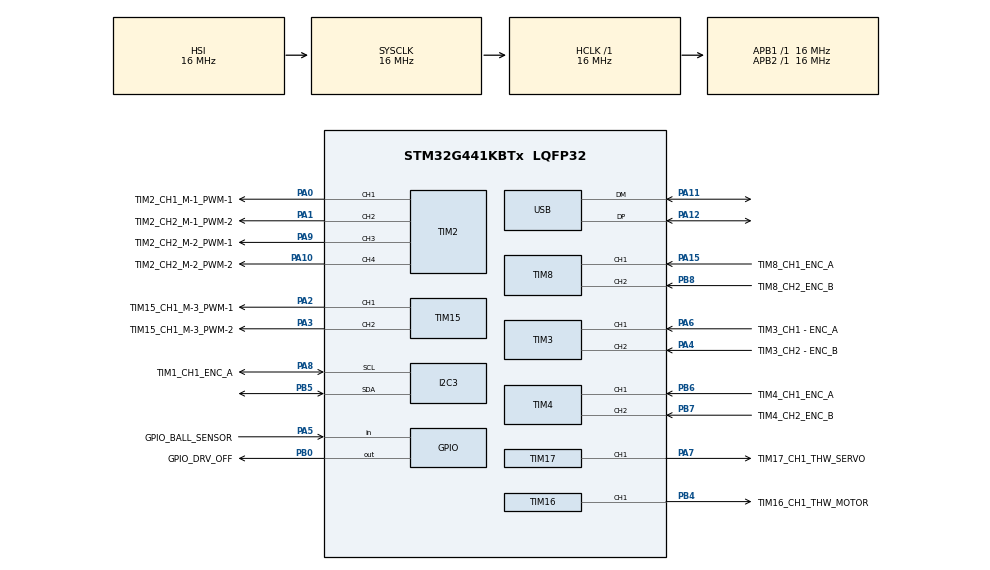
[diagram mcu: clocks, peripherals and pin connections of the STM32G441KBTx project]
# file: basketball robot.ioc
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<<<<<<< HEAD
=======
<<<<<<< HEAD
Mcu.Family=STM32G4
Mcu.Name=STM32G441KBTx
Mcu.Package=LQFP32
NVIC.PriorityGroup=NVIC_PRIORITYGROUP_4
PA0.GPIO_Label=TIM2_CH1_M-1_PWM-1
PA0.Signal=S_TIM2_CH1
PA1.GPIO_Label=TIM2_CH2_M-1_PWM-2
PA1.Signal=S_TIM2_CH2
PA10.GPIO_Label=TIM2_CH2_M-2_PWM-2
PA10.Signal=S_TIM2_CH4
PA11.Mode=Device
PA11.Signal=USB_DM
PA12.Mode=Device
PA12.Signal=USB_DP
PA13.Mode=I2C
PA13.Signal=I2C1_SCL
PA14.Mode=I2C
PA14.Signal=I2C1_SDA
PA15.GPIO_Label=TIM8_CH2_M-3_PWM-1
PA15.Signal=S_TIM8_CH1
PA2.GPIO_Label=TIM2_CH2_M-2_PWM-1
PA2.Signal=S_TIM2_CH3
PA3.GPIO_Label=TIM15_CH2_TH_PWM
PA3.Signal=S_TIM15_CH2
PA4.GPIO_Label=TIM3_CH2 - ENC_B
PA4.Signal=S_TIM3_CH2
PA6.GPIO_Label=TIM3_CH1 - ENC_A
PA6.Signal=S_TIM3_CH1
PA8.GPIO_Label=TIM1_CH1_ENC_A
PA8.Signal=S_TIM1_CH1
PA9.GPIO_Label=TIM1_CH2_ENC_B
PA9.Signal=S_TIM1_CH2
PB6.GPIO_Label=TIM4_CH1_ENC_A
PB6.Signal=S_TIM4_CH1
PB7.GPIO_Label=TIM4_CH2_ENC_B
PB7.Signal=S_TIM4_CH2
PB8-BOOT0.GPIO_Label=TIM8_CH2_M-3_PWM-2 (BOOT0)
PB8-BOOT0.Signal=S_TIM8_CH2
ProjectManager.HeapSize=0x200
ProjectManager.StackSize=0x400
ProjectManager.TargetToolchain=STM32CubeIDE
RCC.AHBFreq_Value=16000000
RCC.APB1Freq_Value=16000000
RCC.APB1TimFreq_Value=16000000
RCC.APB2Freq_Value=16000000
RCC.APB2TimFreq_Value=16000000
RCC.CortexFreq_Value=16000000
RCC.EXTERNAL_CLOCK_VALUE=12288000
RCC.HCLKFreq_Value=16000000
RCC.HSE_VALUE=8000000
RCC.HSI48_VALUE=48000000
RCC.HSI_VALUE=16000000
RCC.LSE_VALUE=32768
RCC.PLLN=12
RCC.PLLQ=RCC_PLLQ_DIV4
RCC.SYSCLKFreq_VALUE=16000000
RCC.USBFreq_Value=48000000
RCC.VCOOutputFreq_Value=192000000
SH.S_TIM15_CH2.0=TIM15_CH2,PWM Generation2 CH2
SH.S_TIM1_CH1.0=TIM1_CH1,Encoder_Interface
SH.S_TIM1_CH2.0=TIM1_CH2,Encoder_Interface
SH.S_TIM2_CH1.0=TIM2_CH1,PWM Generation1 CH1
SH.S_TIM2_CH2.0=TIM2_CH2,PWM Generation2 CH2
SH.S_TIM2_CH3.0=TIM2_CH3,PWM Generation3 CH3
SH.S_TIM2_CH4.0=TIM2_CH4,PWM Generation4 CH4
SH.S_TIM3_CH1.0=TIM3_CH1,Encoder_Interface
SH.S_TIM3_CH2.0=TIM3_CH2,Encoder_Interface
SH.S_TIM4_CH1.0=TIM4_CH1,Encoder_Interface
SH.S_TIM4_CH2.0=TIM4_CH2,Encoder_Interface
SH.S_TIM8_CH1.0=TIM8_CH1,Output Compare1 CH1
SH.S_TIM8_CH2.0=TIM8_CH2,Output Compare2 CH2
TIM15.Channel-PWM\ Generation2\ CH2=TIM_CHANNEL_2
TIM2.Channel-PWM\ Generation1\ CH1=TIM_CHANNEL_1
TIM2.Channel-PWM\ Generation2\ CH2=TIM_CHANNEL_2
TIM2.Channel-PWM\ Generation3\ CH3=TIM_CHANNEL_3
TIM2.Channel-PWM\ Generation4\ CH4=TIM_CHANNEL_4
TIM8.Channel-Output\ Compare1\ CH1=TIM_CHANNEL_1
TIM8.Channel-Output\ Compare2\ CH2=TIM_CHANNEL_2
USB.battery_charging_enable=DISABLE
USB.low_power_enable=DISABLE
USB.lpm_enable=DISABLE
VP_SYS_VS_DBSignals.Mode=DisableDeadBatterySignals
board=custom
=======
>>>>>>> 8d38ac2402675cea33a5d87779682db3a0426ee8
Mcu.Family=STM32G4
Mcu.Name=STM32G441KBTx
Mcu.Package=LQFP32
NVIC.PriorityGroup=NVIC_PRIORITYGROUP_4
PA0.GPIO_Label=TIM2_CH1_M-1_PWM-1
PA0.Signal=S_TIM2_CH1
PA1.GPIO_Label=TIM2_CH2_M-1_PWM-2
PA1.Signal=S_TIM2_CH2
PA10.GPIO_Label=TIM2_CH2_M-2_PWM-2
PA10.Signal=S_TIM2_CH4
PA11.Mode=Device
PA11.Signal=USB_DM
PA12.Mode=Device
PA12.Signal=USB_DP
PA13.Mode=Serial_Wire
PA13.Signal=SYS_JTMS-SWDIO
PA14.Mode=Serial_Wire
PA14.Signal=SYS_JTCK-SWCLK
PA15.GPIO_Label=TIM8_CH1_ENC_A
PA15.Signal=S_TIM8_CH1
PA2.GPIO_Label=TIM15_CH1_M-3_PWM-1
PA2.Signal=S_TIM15_CH1
PA3.GPIO_Label=TIM15_CH1_M-3_PWM-2
PA3.Signal=S_TIM15_CH2
PA4.GPIO_Label=TIM3_CH2 - ENC_B
PA4.Signal=S_TIM3_CH2
PA5.GPIO_Label=GPIO_BALL_SENSOR
PA5.Signal=GPIO_Input
PA6.GPIO_Label=TIM3_CH1 - ENC_A
PA6.Signal=S_TIM3_CH1
PA7.GPIO_Label=TIM17_CH1_THW_SERVO
PA7.Signal=S_TIM17_CH1
PA8.Mode=I2C
PA8.Signal=I2C3_SCL
PA9.GPIO_Label=TIM2_CH2_M-2_PWM-1
PA9.Signal=S_TIM2_CH3
PB0.GPIO_Label=GPIO_DRV_OFF
PB0.Signal=GPIO_Output
PB4.GPIO_Label=TIM16_CH1_THW_MOTOR
PB4.Signal=S_TIM16_CH1
PB5.Mode=I2C
PB5.Signal=I2C3_SDA
PB6.GPIO_Label=TIM4_CH1_ENC_A
PB6.Signal=S_TIM4_CH1
PB7.GPIO_Label=TIM4_CH2_ENC_B
PB7.Signal=S_TIM4_CH2
PB8-BOOT0.GPIO_Label=TIM8_CH2_ENC_B
PB8-BOOT0.Signal=S_TIM8_CH2
ProjectManager.HeapSize=0x200
ProjectManager.StackSize=0x400
ProjectManager.TargetToolchain=STM32CubeIDE
RCC.AHBFreq_Value=16000000
RCC.APB1Freq_Value=16000000
RCC.APB1TimFreq_Value=16000000
RCC.APB2Freq_Value=16000000
RCC.APB2TimFreq_Value=16000000
RCC.CortexFreq_Value=16000000
RCC.EXTERNAL_CLOCK_VALUE=12288000
RCC.HCLKFreq_Value=16000000
RCC.HSE_VALUE=8000000
RCC.HSI48_VALUE=48000000
RCC.HSI_VALUE=16000000
RCC.LSE_VALUE=32768
RCC.PLLN=12
RCC.PLLQ=RCC_PLLQ_DIV4
RCC.SYSCLKFreq_VALUE=16000000
RCC.USBFreq_Value=48000000
RCC.VCOOutputFreq_Value=192000000
SH.S_TIM15_CH1.0=TIM15_CH1,PWM Generation1 CH1
SH.S_TIM15_CH2.0=TIM15_CH2,PWM Generation2 CH2
SH.S_TIM16_CH1.0=TIM16_CH1,PWM Generation1 CH1
SH.S_TIM17_CH1.0=TIM17_CH1,PWM Generation1 CH1
SH.S_TIM2_CH1.0=TIM2_CH1,PWM Generation1 CH1
SH.S_TIM2_CH2.0=TIM2_CH2,PWM Generation2 CH2
SH.S_TIM2_CH3.0=TIM2_CH3,PWM Generation3 CH3
SH.S_TIM2_CH4.0=TIM2_CH4,PWM Generation4 CH4
SH.S_TIM3_CH1.0=TIM3_CH1,Encoder_Interface
SH.S_TIM3_CH2.0=TIM3_CH2,Encoder_Interface
SH.S_TIM4_CH1.0=TIM4_CH1,Encoder_Interface
SH.S_TIM4_CH2.0=TIM4_CH2,Encoder_Interface
SH.S_TIM8_CH1.0=TIM8_CH1,Encoder_Interface
SH.S_TIM8_CH2.0=TIM8_CH2,Encoder_Interface
TIM15.Channel-PWM\ Generation1\ CH1=TIM_CHANNEL_1
TIM15.Channel-PWM\ Generation2\ CH2=TIM_CHANNEL_2
TIM16.Channel=TIM_CHANNEL_1
TIM17.Channel=TIM_CHANNEL_1
TIM2.Channel-PWM\ Generation1\ CH1=TIM_CHANNEL_1
TIM2.Channel-PWM\ Generation2\ CH2=TIM_CHANNEL_2
TIM2.Channel-PWM\ Generation3\ CH3=TIM_CHANNEL_3
TIM2.Channel-PWM\ Generation4\ CH4=TIM_CHANNEL_4
USB.battery_charging_enable=DISABLE
USB.low_power_enable=DISABLE
USB.lpm_enable=DISABLE
VP_SYS_VS_DBSignals.Mode=DisableDeadBatterySignals
VP_TIM16_VS_ClockSourceINT.Mode=Enable_Timer
VP_TIM17_VS_ClockSourceINT.Mode=Enable_Timer
board=custom
<<<<<<< HEAD
=======
>>>>>>> peeter
>>>>>>> 8d38ac2402675cea33a5d87779682db3a0426ee8

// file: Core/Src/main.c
/* USER CODE BEGIN Header */
/**
  ******************************************************************************
  * @file           : main.c
  * @brief          : Main program body
  ******************************************************************************
  * @attention
  *
  * Copyright (c) 2021 STMicroelectronics.
  * All rights reserved.
  *
  * This software is licensed under terms that can be found in the LICENSE file
  * in the root directory of this software component.
  * If no LICENSE file comes with this software, it is provided AS-IS.
  *
  ******************************************************************************
  */
/* USER CODE END Header  */
#include "main.h"

/* USER CODE BEGIN Includes */
#include "mpu6050.h"
/* USER CODE END Includes */

I2C_HandleTypeDef hi2c3;

TIM_HandleTypeDef htim2;
TIM_HandleTypeDef htim3;
TIM_HandleTypeDef htim4;
TIM_HandleTypeDef htim8;
TIM_HandleTypeDef htim15;
TIM_HandleTypeDef htim16;
TIM_HandleTypeDef htim17;

PCD_HandleTypeDef hpcd_USB_FS;

/* USER CODE BEGIN PV */
MPU6050_t MPU6050;
/* USER CODE END PV */

void SystemClock_Config(void);
static void MX_GPIO_Init(void);
static void MX_TIM2_Init(void);
static void MX_TIM3_Init(void);
static void MX_USB_PCD_Init(void);
static void MX_TIM4_Init(void);
static void MX_TIM8_Init(void);
static void MX_TIM15_Init(void);
static void MX_I2C3_Init(void);
static void MX_TIM16_Init(void);
static void MX_TIM17_Init(void);

int main(void)
{

  /* MCU Configuration--------------------------------------------------------*/

  /* Reset of all peripherals, Initializes the Flash interface and the Systick. */
  HAL_Init();

  /* Configure the system clock */
  SystemClock_Config();

  /* Initialize all configured peripherals */
  MX_GPIO_Init();
  MX_TIM2_Init();
  MX_TIM3_Init();
  MX_USB_PCD_Init();
  MX_TIM4_Init();
  MX_TIM8_Init();
  MX_TIM15_Init();
  MX_I2C3_Init();
  MX_TIM16_Init();
  MX_TIM17_Init();
  /* USER CODE BEGIN 2 */
  while (MPU6050_Init(&hi2c3) == 1);
  /* USER CODE END 2 */

  /* Infinite loop */
  while (1)
  {

    /* USER CODE BEGIN 3 */
	  MPU6050_Read_All(&hi2c3, &MPU6050);
	  HAL_Delay (100);
  }
  /* USER CODE END 3 */
}

void SystemClock_Config(void)
{
  RCC_OscInitTypeDef RCC_OscInitStruct = {0};
  RCC_ClkInitTypeDef RCC_ClkInitStruct = {0};

  /** Configure the main internal regulator output voltage
  */
  HAL_PWREx_ControlVoltageScaling(PWR_REGULATOR_VOLTAGE_SCALE1);
  /** Initializes the RCC Oscillators according to the specified parameters
  * in the RCC_OscInitTypeDef structure.
  */
  RCC_OscInitStruct.OscillatorType = RCC_OSCILLATORTYPE_HSI;
  RCC_OscInitStruct.HSIState = RCC_HSI_ON;
  RCC_OscInitStruct.HSICalibrationValue = RCC_HSICALIBRATION_DEFAULT;
  RCC_OscInitStruct.PLL.PLLState =
		  RCC_PLL_ON;
  RCC_OscInitStruct.PLL.PLLSource = RCC_PLLSOURCE_HSI;
  RCC_OscInitStruct.PLL.PLLM = RCC_PLLM_DIV1;
  RCC_OscInitStruct.PLL.PLLN = 12;
  RCC_OscInitStruct.PLL.PLLP = RCC_PLLP_DIV2;
  RCC_OscInitStruct.PLL.PLLQ = RCC_PLLQ_DIV4;
  RCC_OscInitStruct.PLL.PLLR = RCC_PLLR_DIV2;
  if (HAL_RCC_OscConfig(&RCC_OscInitStruct) != HAL_OK)
  {
    Error_Handler();
  }
  /** Initializes the CPU, AHB and APB buses clocks
  */
  RCC_ClkInitStruct.ClockType = RCC_CLOCKTYPE_HCLK|RCC_CLOCKTYPE_SYSCLK
                              |RCC_CLOCKTYPE_PCLK1|RCC_CLOCKTYPE_PCLK2;
  RCC_ClkInitStruct.SYSCLKSource = RCC_SYSCLKSOURCE_HSI;
  RCC_ClkInitStruct.AHBCLKDivider = RCC_SYSCLK_DIV1;
  RCC_ClkInitStruct.APB1CLKDivider = RCC_HCLK_DIV1;
  RCC_ClkInitStruct.APB2CLKDivider = RCC_HCLK_DIV1;

  if (HAL_RCC_ClockConfig(&RCC_ClkInitStruct, FLASH_LATENCY_0) != HAL_OK)
  {
    Error_Handler();
  }
}

static void MX_I2C3_Init(void)
{

  hi2c3.Instance = I2C3;
  hi2c3.Init.Timing = 0x00303D5B;
  hi2c3.Init.OwnAddress1 = 0;
  hi2c3.Init.AddressingMode = I2C_ADDRESSINGMODE_7BIT;
  hi2c3.Init.DualAddressMode = I2C_DUALADDRESS_DISABLE;
  hi2c3.Init.OwnAddress2 = 0;
  hi2c3.Init.OwnAddress2Masks = I2C_OA2_NOMASK;
  hi2c3.Init.GeneralCallMode = I2C_GENERALCALL_DISABLE;
  hi2c3.Init.NoStretchMode = I2C_NOSTRETCH_DISABLE;
  if (HAL_I2C_Init(&hi2c3) != HAL_OK)
  {
    Error_Handler();
  }
  /** Configure Analogue filter
  */
  if (HAL_I2CEx_ConfigAnalogFilter(&hi2c3, I2C_ANALOGFILTER_ENABLE) != HAL_OK)
  {
    Error_Handler();
  }
  /** Configure Digital filter
  */
  if (HAL_I2CEx_ConfigDigitalFilter(&hi2c3, 0) != HAL_OK)
  {
    Error_Handler();
  }

}

static void MX_TIM2_Init(void)
{

  TIM_MasterConfigTypeDef sMasterConfig = {0};
  TIM_OC_InitTypeDef sConfigOC = {0};

  htim2.Instance = TIM2;
  htim2.Init.Prescaler = 0;
  htim2.Init.CounterMode = TIM_COUNTERMODE_UP;
  htim2.Init.Period = 4.294967295E9;
  htim2.Init.ClockDivision = TIM_CLOCKDIVISION_DIV1;
  htim2.Init.AutoReloadPreload = TIM_AUTORELOAD_PRELOAD_DISABLE;
  if (HAL_TIM_PWM_Init(&htim2) != HAL_OK)
  {
    Error_Handler();
  }
  sMasterConfig.MasterOutputTrigger = TIM_TRGO_RESET;
  sMasterConfig.MasterSlaveMode = TIM_MASTERSLAVEMODE_DISABLE;
  if (HAL_TIMEx_MasterConfigSynchronization(&htim2, &sMasterConfig) != HAL_OK)
  {
    Error_Handler();
  }
  sConfigOC.OCMode = TIM_OCMODE_PWM1;
  sConfigOC.Pulse = 0;
  sConfigOC.OCPolarity = TIM_OCPOLARITY_HIGH;
  sConfigOC.OCFastMode = TIM_OCFAST_DISABLE;
  if (HAL_TIM_PWM_ConfigChannel(&htim2, &sConfigOC, TIM_CHANNEL_1) != HAL_OK)
  {
    Error_Handler();
  }
  if (HAL_TIM_PWM_ConfigChannel(&htim2, &sConfigOC, TIM_CHANNEL_2) != HAL_OK)
  {
    Error_Handler();
  }
  if (HAL_TIM_PWM_ConfigChannel(&htim2, &sConfigOC, TIM_CHANNEL_3) != HAL_OK)
  {
    Error_Handler();
  }
  if (HAL_TIM_PWM_ConfigChannel(&htim2, &sConfigOC, TIM_CHANNEL_4) != HAL_OK)
  {
    Error_Handler();
  }
  HAL_TIM_MspPostInit(&htim2);

}

static void MX_TIM3_Init(void)
{

  TIM_Encoder_InitTypeDef sConfig = {0};
  TIM_MasterConfigTypeDef sMasterConfig = {0};

  htim3.Instance = TIM3;
  htim3.Init.Prescaler = 0;
  htim3.Init.CounterMode = TIM_COUNTERMODE_UP;
  htim3.Init.Period = 65535;
  htim3.Init.ClockDivision = TIM_CLOCKDIVISION_DIV1;
  htim3.Init.AutoReloadPreload = TIM_AUTORELOAD_PRELOAD_DISABLE;
  sConfig.EncoderMode = TIM_ENCODERMODE_TI1;
  sConfig.IC1Polarity = TIM_ICPOLARITY_RISING;
  sConfig.IC1Selection = TIM_ICSELECTION_DIRECTTI;
  sConfig.IC1Prescaler = TIM_ICPSC_DIV1;
  sConfig.IC1Filter = 0;
  sConfig.IC2Polarity = TIM_ICPOLARITY_RISING;
  sConfig.IC2Selection = TIM_ICSELECTION_DIRECTTI;
  sConfig.IC2Prescaler = TIM_ICPSC_DIV1;
  sConfig.IC2Filter = 0;
  if (HAL_TIM_Encoder_Init(&htim3, &sConfig) != HAL_OK)
  {
    Error_Handler();
  }
  sMasterConfig.MasterOutputTrigger = TIM_TRGO_RESET;
  sMasterConfig.MasterSlaveMode = TIM_MASTERSLAVEMODE_DISABLE;
  if (HAL_TIMEx_MasterConfigSynchronization(&htim3, &sMasterConfig) != HAL_OK)
  {
    Error_Handler();
  }

}

static void MX_TIM4_Init(void)
{

  TIM_Encoder_InitTypeDef sConfig = {0};
  TIM_MasterConfigTypeDef sMasterConfig = {0};

  htim4.Instance = TIM4;
  htim4.Init.Prescaler = 0;
  htim4.Init.CounterMode = TIM_COUNTERMODE_UP;
  htim4.Init.Period = 65535;
  htim4.Init.ClockDivision = TIM_CLOCKDIVISION_DIV1;
  htim4.Init.AutoReloadPreload = TIM_AUTORELOAD_PRELOAD_DISABLE;
  sConfig.EncoderMode = TIM_ENCODERMODE_TI1;
  sConfig.IC1Polarity = TIM_ICPOLARITY_RISING;
  sConfig.IC1Selection = TIM_ICSELECTION_DIRECTTI;
  sConfig.IC1Prescaler = TIM_ICPSC_DIV1;
  sConfig.IC1Filter = 0;
  sConfig.IC2Polarity = TIM_ICPOLARITY_RISING;
  sConfig.IC2Selection = TIM_ICSELECTION_DIRECTTI;
  sConfig.IC2Prescaler = TIM_ICPSC_DIV1;
  sConfig.IC2Filter = 0;
  if (HAL_TIM_Encoder_Init(&htim4, &sConfig) != HAL_OK)
  {
    Error_Handler();
  }
  sMasterConfig.MasterOutputTrigger = TIM_TRGO_RESET;
  sMasterConfig.MasterSlaveMode = TIM_MASTERSLAVEMODE_DISABLE;
  if (HAL_TIMEx_MasterConfigSynchronization(&htim4, &sMasterConfig) != HAL_OK)
  {
    Error_Handler();
  }

}

static void MX_TIM8_Init(void)
{

  TIM_Encoder_InitTypeDef sConfig = {0};
  TIM_MasterConfigTypeDef sMasterConfig = {0};

  htim8.Instance = TIM8;
  htim8.Init.Prescaler = 0;
  htim8.Init.CounterMode = TIM_COUNTERMODE_UP;
  htim8.Init.Period = 65535;
  htim8.Init.ClockDivision = TIM_CLOCKDIVISION_DIV1;
  htim8.Init.RepetitionCounter = 0;
  htim8.Init.AutoReloadPreload = TIM_AUTORELOAD_PRELOAD_DISABLE;
  sConfig.EncoderMode = TIM_ENCODERMODE_TI1;
  sConfig.IC1Polarity = TIM_ICPOLARITY_RISING;
  sConfig.IC1Selection = TIM_ICSELECTION_DIRECTTI;
  sConfig.IC1Prescaler = TIM_ICPSC_DIV1;
  sConfig.IC1Filter = 0;
  sConfig.IC2Polarity = TIM_ICPOLARITY_RISING;
  sConfig.IC2Selection = TIM_ICSELECTION_DIRECTTI;
  sConfig.IC2Prescaler = TIM_ICPSC_DIV1;
  sConfig.IC2Filter = 0;
  if (HAL_TIM_Encoder_Init(&htim8, &sConfig) != HAL_OK)
  {
    Error_Handler();
  }
  sMasterConfig.MasterOutputTrigger = TIM_TRGO_RESET;
  sMasterConfig.MasterOutputTrigger2 = TIM_TRGO2_RESET;
  sMasterConfig.MasterSlaveMode = TIM_MASTERSLAVEMODE_DISABLE;
  if (HAL_TIMEx_MasterConfigSynchronization(&htim8, &sMasterConfig) != HAL_OK)
  {
    Error_Handler();
  }

}

static void MX_TIM15_Init(void)
{

  TIM_MasterConfigTypeDef sMasterConfig = {0};
  TIM_OC_InitTypeDef sConfigOC = {0};
  TIM_BreakDeadTimeConfigTypeDef sBreakDeadTimeConfig = {0};

  htim15.Instance = TIM15;
  htim15.Init.Prescaler = 0;
  htim15.Init.CounterMode = TIM_COUNTERMODE_UP;
  htim15.Init.Period = 65535;
  htim15.Init.ClockDivision = TIM_CLOCKDIVISION_DIV1;
  htim15.Init.RepetitionCounter = 0;
  htim15.Init.AutoReloadPreload = TIM_AUTORELOAD_PRELOAD_DISABLE;
  if (HAL_TIM_PWM_Init(&htim15) != HAL_OK)
  {
    Error_Handler();
  }
  sMasterConfig.MasterOutputTrigger = TIM_TRGO_RESET;
  sMasterConfig.MasterSlaveMode = TIM_MASTERSLAVEMODE_DISABLE;
  if (HAL_TIMEx_MasterConfigSynchronization(&htim15, &sMasterConfig) != HAL_OK)
  {
    Error_Handler();
  }
  sConfigOC.OCMode = TIM_OCMODE_PWM1;
  sConfigOC.Pulse = 0;
  sConfigOC.OCPolarity = TIM_OCPOLARITY_HIGH;
  sConfigOC.OCNPolarity = TIM_OCNPOLARITY_HIGH;
  sConfigOC.OCFastMode = TIM_OCFAST_DISABLE;
  sConfigOC.OCIdleState = TIM_OCIDLESTATE_RESET;
  sConfigOC.OCNIdleState = TIM_OCNIDLESTATE_RESET;
  if (HAL_TIM_PWM_ConfigChannel(&htim15, &sConfigOC, TIM_CHANNEL_1) != HAL_OK)
  {
    Error_Handler();
  }
  if (HAL_TIM_PWM_ConfigChannel(&htim15, &sConfigOC, TIM_CHANNEL_2) != HAL_OK)
  {
    Error_Handler();
  }
  sBreakDeadTimeConfig.OffStateRunMode = TIM_OSSR_DISABLE;
  sBreakDeadTimeConfig.OffStateIDLEMode = TIM_OSSI_DISABLE;
  sBreakDeadTimeConfig.LockLevel = TIM_LOCKLEVEL_OFF;
  sBreakDeadTimeConfig.DeadTime = 0;
  sBreakDeadTimeConfig.BreakState = TIM_BREAK_DISABLE;
  sBreakDeadTimeConfig.BreakPolarity = TIM_BREAKPOLARITY_HIGH;
  sBreakDeadTimeConfig.BreakFilter = 0;
  sBreakDeadTimeConfig.AutomaticOutput = TIM_AUTOMATICOUTPUT_DISABLE;
  if (HAL_TIMEx_ConfigBreakDeadTime(&htim15, &sBreakDeadTimeConfig) != HAL_OK)
  {
    Error_Handler();
  }
  HAL_TIM_MspPostInit(&htim15);

}

static void MX_TIM16_Init(void)
{

  TIM_OC_InitTypeDef sConfigOC = {0};
  TIM_BreakDeadTimeConfigTypeDef sBreakDeadTimeConfig = {0};

  htim16.Instance = TIM16;
  htim16.Init.Prescaler = 0;
  htim16.Init.CounterMode = TIM_COUNTERMODE_UP;
  htim16.Init.Period = 65535;
  htim16.Init.ClockDivision = TIM_CLOCKDIVISION_DIV1;
  htim16.Init.RepetitionCounter = 0;
  htim16.Init.AutoReloadPreload = TIM_AUTORELOAD_PRELOAD_DISABLE;
  if (HAL_TIM_Base_Init(&htim16) != HAL_OK)
  {
    Error_Handler();
  }
  if (HAL_TIM_PWM_Init(&htim16) != HAL_OK)
  {
    Error_Handler();
  }
  sConfigOC.OCMode = TIM_OCMODE_PWM1;
  sConfigOC.Pulse = 0;
  sConfigOC.OCPolarity = TIM_OCPOLARITY_HIGH;
  sConfigOC.OCNPolarity = TIM_OCNPOLARITY_HIGH;
  sConfigOC.OCFastMode = TIM_OCFAST_DISABLE;
  sConfigOC.OCIdleState = TIM_OCIDLESTATE_RESET;
  sConfigOC.OCNIdleState = TIM_OCNIDLESTATE_RESET;
  if (HAL_TIM_PWM_ConfigChannel(&htim16, &sConfigOC, TIM_CHANNEL_1) != HAL_OK)
  {
    Error_Handler();
  }
  sBreakDeadTimeConfig.OffStateRunMode = TIM_OSSR_DISABLE;
  sBreakDeadTimeConfig.OffStateIDLEMode = TIM_OSSI_DISABLE;
  sBreakDeadTimeConfig.LockLevel = TIM_LOCKLEVEL_OFF;
  sBreakDeadTimeConfig.DeadTime = 0;
  sBreakDeadTimeConfig.BreakState = TIM_BREAK_DISABLE;
  sBreakDeadTimeConfig.BreakPolarity = TIM_BREAKPOLARITY_HIGH;
  sBreakDeadTimeConfig.BreakFilter = 0;
  sBreakDeadTimeConfig.AutomaticOutput = TIM_AUTOMATICOUTPUT_DISABLE;
  if (HAL_TIMEx_ConfigBreakDeadTime(&htim16, &sBreakDeadTimeConfig) != HAL_OK)
  {
    Error_Handler();
  }
  HAL_TIM_MspPostInit(&htim16);

}

static void MX_TIM17_Init(void)
{

  TIM_OC_InitTypeDef sConfigOC = {0};
  TIM_BreakDeadTimeConfigTypeDef sBreakDeadTimeConfig = {0};

  htim17.Instance = TIM17;
  htim17.Init.Prescaler = 0;
  htim17.Init.CounterMode = TIM_COUNTERMODE_UP;
  htim17.Init.Period = 65535;
  htim17.Init.ClockDivision = TIM_CLOCKDIVISION_DIV1;
  htim17.Init.RepetitionCounter = 0;
  htim17.Init.AutoReloadPreload = TIM_AUTORELOAD_PRELOAD_DISABLE;
  if (HAL_TIM_Base_Init(&htim17) != HAL_OK)
  {
    Error_Handler();
  }
  if (HAL_TIM_PWM_Init(&htim17) != HAL_OK)
  {
    Error_Handler();
  }
  sConfigOC.OCMode = TIM_OCMODE_PWM1;
  sConfigOC.Pulse = 0;
  sConfigOC.OCPolarity = TIM_OCPOLARITY_HIGH;
  sConfigOC.OCNPolarity = TIM_OCNPOLARITY_HIGH;
  sConfigOC.OCFastMode = TIM_OCFAST_DISABLE;
  sConfigOC.OCIdleState = TIM_OCIDLESTATE_RESET;
  sConfigOC.OCNIdleState = TIM_OCNIDLESTATE_RESET;
  if (HAL_TIM_PWM_ConfigChannel(&htim17, &sConfigOC, TIM_CHANNEL_1) != HAL_OK)
  {
    Error_Handler();
  }
  sBreakDeadTimeConfig.OffStateRunMode = TIM_OSSR_DISABLE;
  sBreakDeadTimeConfig.OffStateIDLEMode = TIM_OSSI_DISABLE;
  sBreakDeadTimeConfig.LockLevel = TIM_LOCKLEVEL_OFF;
  sBreakDeadTimeConfig.DeadTime = 0;
  sBreakDeadTimeConfig.BreakState = TIM_BREAK_DISABLE;
  sBreakDeadTimeConfig.BreakPolarity = TIM_BREAKPOLARITY_HIGH;
  sBreakDeadTimeConfig.BreakFilter = 0;
  sBreakDeadTimeConfig.AutomaticOutput = TIM_AUTOMATICOUTPUT_DISABLE;
  if (HAL_TIMEx_ConfigBreakDeadTime(&htim17, &sBreakDeadTimeConfig) != HAL_OK)
  {
    Error_Handler();
  }
  HAL_TIM_MspPostInit(&htim17);

}

static void MX_USB_PCD_Init(void)
{

  hpcd_USB_FS.Instance = USB;
  hpcd_USB_FS.Init.dev_endpoints = 8;
  hpcd_USB_FS.Init.speed = PCD_SPEED_FULL;
  hpcd_USB_FS.Init.phy_itface = PCD_PHY_EMBEDDED;
  hpcd_USB_FS.Init.Sof_enable = DISABLE;
  hpcd_USB_FS.Init.low_power_enable = DISABLE;
  hpcd_USB_FS.Init.lpm_enable = DISABLE;
  hpcd_USB_FS.Init.battery_charging_enable = DISABLE;
  if (HAL_PCD_Init(&hpcd_USB_FS) != HAL_OK)
  {
    Error_Handler();
  }

}

static void MX_GPIO_Init(void)
{
  GPIO_InitTypeDef GPIO_InitStruct = {0};

  /* GPIO Ports Clock Enable */
  __HAL_RCC_GPIOA_CLK_ENABLE();
  __HAL_RCC_GPIOB_CLK_ENABLE();

  /*Configure GPIO pin Output Level */
  HAL_GPIO_WritePin(GPIO_DRV_OFF_GPIO_Port, GPIO_DRV_OFF_Pin, GPIO_PIN_RESET);

  /*Configure GPIO pin : GPIO_BALL_SENSOR_Pin */
  GPIO_InitStruct.Pin = GPIO_BALL_SENSOR_Pin;
  GPIO_InitStruct.Mode = GPIO_MODE_INPUT;
  GPIO_InitStruct.Pull = GPIO_NOPULL;
  HAL_GPIO_Init(GPIO_BALL_SENSOR_GPIO_Port, &GPIO_InitStruct);

  /*Configure GPIO pin : GPIO_DRV_OFF_Pin */
  GPIO_InitStruct.Pin = GPIO_DRV_OFF_Pin;
  GPIO_InitStruct.Mode = GPIO_MODE_OUTPUT_PP;
  GPIO_InitStruct.Pull = GPIO_NOPULL;
  GPIO_InitStruct.Speed = GPIO_SPEED_FREQ_LOW;
  HAL_GPIO_Init(GPIO_DRV_OFF_GPIO_Port, &GPIO_InitStruct);

}

void Error_Handler(void)
{
  __disable_irq();
  while (1)
  {
  }
}
